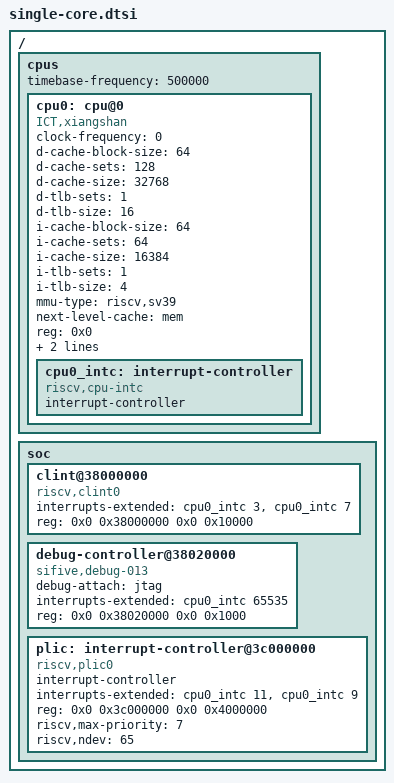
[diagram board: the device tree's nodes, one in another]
/ {
	cpus {
		#address-cells = <1>;
		#size-cells = <0>;
		timebase-frequency = <500000>;// clk freq / 100
		cpu0: cpu@0 {
			clock-frequency = <0>;
			compatible = "ICT,xiangshan", "riscv";
			d-cache-block-size = <64>;
			d-cache-sets = <128>;
			d-cache-size = <32768>;
			d-tlb-sets = <1>;
			d-tlb-size = <16>;
			device_type = "cpu";
			i-cache-block-size = <64>;
			i-cache-sets = <64>;
			i-cache-size = <16384>;
			i-tlb-sets = <1>;
			i-tlb-size = <4>;
			mmu-type = "riscv,sv39";
			next-level-cache = <&mem>;
			reg = <0x0>;
			riscv,isa = "rv64imafdc";
			status = "okay";
			tlb-split;
			cpu0_intc: interrupt-controller {
				#address-cells = <0>;
				#interrupt-cells = <1>;
				compatible = "riscv,cpu-intc";
				interrupt-controller;
			};
		};
	};
	
	soc {
		clint@38000000 {
			compatible = "riscv,clint0";
			interrupts-extended = <&cpu0_intc 3 &cpu0_intc 7>;
			reg = <0x0 0x38000000 0x0 0x10000>;
			reg-names = "control";
		};
		debug-controller@38020000 {
			compatible = "sifive,debug-013", "riscv,debug-013";
			debug-attach = "jtag";
			interrupts-extended = <&cpu0_intc 65535>;
			reg = <0x0 0x38020000 0x0 0x1000>;
			reg-names = "control";
		};
		plic: interrupt-controller@3c000000 {
			#address-cells = <2>;
			#interrupt-cells = <1>;
			compatible = "riscv,plic0";
			interrupt-controller;
			interrupts-extended = <&cpu0_intc 11 &cpu0_intc 9>;
			reg = <0x0 0x3c000000 0x0 0x4000000>;
			reg-names = "control";
			riscv,max-priority = <7>;
			riscv,ndev = <65>;
		};
	};
};
